# UPD70F3508 register map
Vendor: Renesas; Series: V850E2/Px4; File version: 1.0
CPU: other r0p0, little endian, no MPU, FPU, 4 interrupt priority bits
Registers are 8-bit, read-write, reset 0x0 unless marked. A register's access mark holds for its fields unless they carry their own. Offsets are from the block's base; [hi:lo] are bit positions; {n}, {i} and the like mark numbered series.

## TAUA1 — Timer Array Unit A 1
Base 0xFF809000
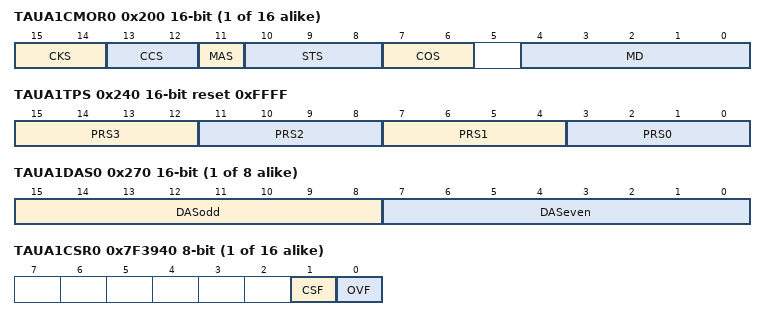
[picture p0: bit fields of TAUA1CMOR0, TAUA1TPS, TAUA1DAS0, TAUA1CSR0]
{0x200+4i} TAUA1CMOR{i} 16-bit (i=0..15) — TAUA1 Channel Mode OS Register {i}
  [15:14] CKS — Sampling clock select [1:0]
  [13:12] CCS — Count clock select [1:0]
  [11] MAS — Master/slave select (even ch only)
  [10:8] STS — External start trigger select [2:0]
  [7:6] COS — Capture update timing [1:0]
  [4:0] MD — Operating mode [4:0]
0x240 TAUA1TPS 16-bit reset 0xFFFF — TAUA1 Prescaler Clock Select Register
  [15:12] PRS3 — CK3_PRE prescaler select [3:0]
  [11:8] PRS2 — CK2 prescaler select [3:0]
  [7:4] PRS1 — CK1 prescaler select [3:0]
  [3:0] PRS0 — CK0 prescaler select [3:0]
0x244 TAUA1BRS — TAUA1 Prescaler Baud Rate Setting Register
  [7:0] BRS — CK3 division coefficient [7:0]
0x248 TAUA1TOM 16-bit — TAUA1 Channel Output Mode Register
  [15:0] TOMm — Output mode per channel: 0=independent 1=synchronous
0x24C TAUA1TOC 16-bit — TAUA1 Channel Output Configuration Register
  [15:0] TOCm — Output config per channel: 0=mode1 1=mode2
0x250 TAUA1TDE 16-bit — TAUA1 Channel Dead Time Output Enable Register
  [15:0] TDEm — Dead time enable per channel
0x254 TAUA1TDM 16-bit — TAUA1 Channel Dead Time Output Mode Register
  [15:0] TDMm — Dead time mode per channel: 0=duty 1=TIN-edge
0x258 TAUA1TRE 16-bit — TAUA1 Channel Real-Time Output Enable Register
  [15:0] TREm — Real-time output enable per channel
0x25C TAUA1TRC 16-bit — TAUA1 Channel Real-Time Output Control Register
  [15:0] TRCm — Real-time trigger channel: 0=next upper 1=self
0x260 TAUA1RDE 16-bit — TAUA1 Channel Reload Data Enable Register
  [15:0] RDEm — Simultaneous rewrite enable per channel
0x264 TAUA1RDM 16-bit — TAUA1 Channel Reload Data Mode Register
  [15:0] RDMm — Simultaneous rewrite timing: 0=master-start 1=triangle-peak
0x268 TAUA1RDS 16-bit — TAUA1 Channel Reload Data Control Channel Select Register
  [15:0] RDSm — Rewrite trigger source per channel: 0=master 1=upper
0x26C TAUA1RDC 16-bit — TAUA1 Channel Reload Data Control Register
  [15:0] RDCm — Simultaneous rewrite trigger channel select
{0x270+4i} TAUA1DAS{i} 16-bit (i=0..7) — TAUA1 DMA Window Address Setting Register {i}
  [15:8] DASodd — Odd channel DMA window address [15:8]
  [7:0] DASeven — Even channel DMA window address [7:0]
{0x7F3800+4i} TAUA1CDR{i} 16-bit (i=0..15) — TAUA1 Channel Data Register {i}
  [15:0] CDR — Capture/compare data [15:0]
0x7F3840 TAUA1TOL 16-bit — TAUA1 Channel Output Active Level Register
  [15:0] TOLm — Output logic per channel: 0=positive 1=inverted
0x7F3844 TAUA1RDT 16-bit wo — TAUA1 Channel Reload Data Trigger Register
  [15:0] RDTm — Trigger simultaneous rewrite pending per channel
0x7F3848 TAUA1RSF 16-bit ro — TAUA1 Channel Reload Status Register
  [15:0] RSFm — Simultaneous rewrite pending status per channel
0x7F384C TAUA1TRO 16-bit — TAUA1 Channel Real-Time Output Register
  [15:0] TROm — Real-time output value per channel: 0=low 1=high
0x7F3850 TAUA1TME 16-bit — TAUA1 Channel Modulation Output Enable Register
  [15:0] TMEm — Modulation output enable per channel
0x7F3854 TAUA1TDL 16-bit — TAUA1 Channel Dead Time Output Level Register
  [15:0] TDLm — Dead time phase per channel: 0=normal 1=reverse
0x7F3858 TAUA1TO 16-bit — TAUA1 Channel Output Register
  [15:0] TOm — Output level per channel: 0=low 1=high
0x7F385C TAUA1TOE 16-bit — TAUA1 Channel Output Enable Register
  [15:0] TOEm — Timer output enable per channel
{0x7F3880+4i} TAUA1CNT{i} 16-bit ro (i=0..15) — TAUA1 Channel Counter Register {i}
  [15:0] CNT — 16-bit counter value
{0x7F38C0+4i} TAUA1CMUR{i} (i=0..15) — TAUA1 Channel Mode User Register {i}
  [1:0] TIS — TIN valid edge select: 00=fall 01=rise 10=both-low 11=both-high
{0x7F3900+4i} TAUA1DWR{i} 16-bit (i=0..15) — TAUA1 DMA Window Register {i}
{0x7F3940+4i} TAUA1CSR{i} ro (i=0..15) — TAUA1 Channel Status Register {i}
  [1] CSF — Count direction: 0=up 1=down
  [0] OVF — Counter overflow flag
{0x7F3980+4i} TAUA1CSC{i} wo (i=0..15) — TAUA1 Channel Status Clear Trigger Register {i}
  [0] CLOV — Clear overflow flag (write 1)
0x7F39C0 TAUA1TE 16-bit ro — TAUA1 Channel Enable Status Register
  [15:0] TEm — Counter enable status per channel
0x7F39C4 TAUA1TS 16-bit wo — TAUA1 Channel Start Trigger Register
  [15:0] TSm — Start counter per channel (write 1)
0x7F39C8 TAUA1TT 16-bit wo — TAUA1 Channel Stop Trigger Register
  [15:0] TTm — Stop counter per channel (write 1)
